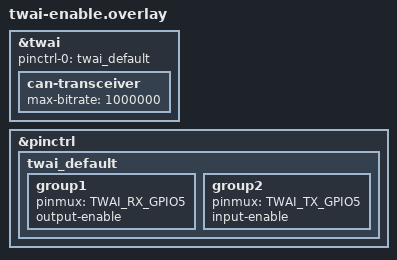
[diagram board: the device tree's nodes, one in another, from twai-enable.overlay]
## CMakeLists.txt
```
# SPDX-License-Identifier: Apache-2.0

cmake_minimum_required(VERSION 3.20.0)
find_package(Zephyr REQUIRED HINTS $ENV{ZEPHYR_BASE})
project(integration)

target_sources(app PRIVATE src/common.c)
target_sources(app PRIVATE src/classic.c)
target_sources(app PRIVATE src/transceiver.c)
target_sources(app PRIVATE src/utilities.c)
target_sources_ifdef(CONFIG_CAN_FD_MODE app PRIVATE src/canfd.c)
target_sources_ifdef(CONFIG_CAN_STATS app PRIVATE src/stats.c)
```

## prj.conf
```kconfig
CONFIG_CAN=y
CONFIG_CAN_FD_MODE=y
CONFIG_CAN_MANUAL_RECOVERY_MODE=y
CONFIG_STATS=y
CONFIG_CAN_STATS=y
CONFIG_TEST_USERSPACE=y
CONFIG_ZTEST=y
# The canfd test suite may be skipped
CONFIG_ZTEST_VERIFY_RUN_ALL=n
```

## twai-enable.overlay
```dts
/*
 * Copyright (c) 2022 Martin Jäger <martin@libre.solar>
 *
 * SPDX-License-Identifier: Apache-2.0
 */

/* Enable CAN bus */
&twai {
	status = "okay";
	pinctrl-0 = <&twai_default>;
	pinctrl-names = "default";

	can-transceiver {
		max-bitrate = <1000000>;
	};
};

&pinctrl {
	twai_default: twai_default {
		group1 {
			pinmux = <TWAI_RX_GPIO5>;
			output-enable;	/* enable internal loopback */
		};
		group2 {
			pinmux = <TWAI_TX_GPIO5>;
			input-enable;	/* enable internal loopback */
		};
};
};
```

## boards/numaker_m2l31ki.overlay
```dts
/* SPDX-License-Identifier: Apache-2.0 */

/ {
	chosen {
		zephyr,canbus = &canfd0;
	};
};

&pinctrl {
	/* CAN TX/RX --> UNO D3/D2 */
	canfd0_default: canfd0_default {
		group0 {
			pinmux = <PC5MFP_CANFD0_TXD>,
				 <PC4MFP_CANFD0_RXD>;
		};
	};
};

&canfd0 {
	pinctrl-0 = <&canfd0_default>;
	pinctrl-names = "default";
	status = "okay";
};
```

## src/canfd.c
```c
/*
 * Copyright (c) 2022 Vestas Wind Systems A/S
 * Copyright (c) 2019 Alexander Wachter
 *
 * SPDX-License-Identifier: Apache-2.0
 */

#include <zephyr/drivers/can.h>
#include <zephyr/ztest.h>

#include "common.h"

/**
 * @addtogroup t_can_driver
 * @{
 * @defgroup t_can_canfd test_can_canfd
 * @}
 */

static void tx_std_callback_1(const struct device *dev, int error, void *user_data)
{
	const struct can_frame *frame = user_data;

	k_sem_give(&tx_callback_sem);

	zassert_equal(dev, can_dev, "CAN device does not match");
	zassert_equal(frame->id, TEST_CAN_STD_ID_1, "ID does not match");
}

static void tx_std_callback_2(const struct device *dev, int error, void *user_data)
{
	const struct can_frame *frame = user_data;

	k_sem_give(&tx_callback_sem);

	zassert_equal(dev, can_dev, "CAN device does not match");
	zassert_equal(frame->id, TEST_CAN_STD_ID_2, "ID does not match");
}

static void rx_std_callback_1(const struct device *dev, struct can_frame *frame, void *user_data)
{
	struct can_filter *filter = user_data;

	assert_frame_equal(frame, &test_std_frame_1, 0);
	zassert_equal(dev, can_dev, "CAN device does not match");
	zassert_equal_ptr(filter, &test_std_filter_1, "filter does not match");

	k_sem_give(&rx_callback_sem);
}

static void rx_std_callback_2(const struct device *dev, struct can_frame *frame, void *user_data)
{
	struct can_filter *filter = user_data;

	assert_frame_equal(frame, &test_std_frame_2, 0);
	zassert_equal(dev, can_dev, "CAN device does not match");
	zassert_equal_ptr(filter, &test_std_filter_2, "filter does not match");

	k_sem_give(&rx_callback_sem);
}

static void rx_std_callback_fd_1(const struct device *dev, struct can_frame *frame,
				 void *user_data)
{
	struct can_filter *filter = user_data;

	assert_frame_equal(frame, &test_std_fdf_frame_1, 0);
	zassert_equal(dev, can_dev, "CAN device does not match");
	zassert_equal_ptr(filter, &test_std_filter_1, "filter does not match");

	k_sem_give(&rx_callback_sem);
}

static void rx_std_callback_fd_2(const struct device *dev, struct can_frame *frame,
				 void *user_data)
{
	struct can_filter *filter = user_data;

	assert_frame_equal(frame, &test_std_fdf_frame_2, 0);
	zassert_equal(dev, can_dev, "CAN device does not match");
	zassert_equal_ptr(filter, &test_std_filter_2, "filter does not match");

	k_sem_give(&rx_callback_sem);
}

/**
 * @brief Send a CAN test frame with asserts.
 *
 * This function will block until the frame is transmitted or a test timeout
 * occurs.
 *
 * @param dev   Pointer to the device structure for the driver instance.
 * @param frame Pointer to the CAN frame to send.
 */
static void send_test_frame(const struct device *dev, const struct can_frame *frame)
{
	int err;

	err = can_send(dev, frame, TEST_SEND_TIMEOUT, NULL, NULL);
	zassert_not_equal(err, -EBUSY, "arbitration lost in loopback mode");
	zassert_equal(err, 0, "failed to send frame (err %d)", err);
}

/**
 * @brief Send a CAN test frame with asserts.
 *
 * This function will block until the frame is queued or a test timeout
 * occurs.
 *
 * @param dev      Pointer to the device structure for the driver instance.
 * @param frame    Pointer to the CAN frame to send.
 * @param callback Transmit callback function.
 */
static void send_test_frame_nowait(const struct device *dev, const struct can_frame *frame,
				   can_tx_callback_t callback)
{
	int err;

	err = can_send(dev, frame, TEST_SEND_TIMEOUT, callback, (void *)frame);
	zassert_not_equal(err, -EBUSY, "arbitration lost in loopback mode");
	zassert_equal(err, 0, "failed to send frame (err %d)", err);
}

/**
 * @brief Add a CAN message queue with asserts.
 *
 * @param dev    Pointer to the device structure for the driver instance.
 * @param filter CAN filter for the CAN message queue.
 *
 * @return CAN filter ID.
 */
static inline int add_rx_msgq(const struct device *dev, const struct can_filter *filter)
{
	int filter_id;

	filter_id = can_add_rx_filter_msgq(dev, &can_msgq, filter);
	zassert_not_equal(filter_id, -ENOSPC, "no filters available");
	zassert_true(filter_id >= 0, "negative filter number");

	return filter_id;
}

/**
 * @brief Add a CAN filter with asserts.
 *
 * @param dev      Pointer to the device structure for the driver instance.
 * @param filter   CAN filter.
 * @param callback Receive callback function.
 *
 * @return CAN filter ID.
 */
static inline int add_rx_filter(const struct device *dev,
				const struct can_filter *filter,
				can_rx_callback_t callback)
{
	int filter_id;

	k_sem_reset(&rx_callback_sem);

	filter_id = can_add_rx_filter(dev, callback, (void *)filter, filter);
	zassert_not_equal(filter_id, -ENOSPC, "no filters available");
	zassert_true(filter_id >= 0, "negative filter number");

	return filter_id;
}

/**
 * @brief Perform a send/receive test with a set of CAN ID filters and CAN frames.
 *
 * @param filter1 CAN filter 1
 * @param filter2 CAN filter 2
 * @param frame1  CAN frame 1
 * @param frame2  CAN frame 2
 */
static void send_receive(const struct can_filter *filter1,
			 const struct can_filter *filter2,
			 const struct can_frame *frame1,
			 const struct can_frame *frame2)
{
	struct can_frame frame_buffer;
	int filter_id_1;
	int filter_id_2;
	int err;

	filter_id_1 = add_rx_msgq(can_dev, filter1);
	send_test_frame(can_dev, frame1);

	err = k_msgq_get(&can_msgq, &frame_buffer, TEST_RECEIVE_TIMEOUT);
	zassert_equal(err, 0, "receive timeout");

	assert_frame_equal(&frame_buffer, frame1, 0);
	can_remove_rx_filter(can_dev, filter_id_1);

	k_sem_reset(&tx_callback_sem);

	if ((frame1->flags & CAN_FRAME_FDF) != 0) {
		filter_id_1 = add_rx_filter(can_dev, filter1, rx_std_callback_fd_1);
	} else {
		filter_id_1 = add_rx_filter(can_dev, filter1, rx_std_callback_1);
	}

	if ((frame2->flags & CAN_FRAME_FDF) != 0) {
		filter_id_2 = add_rx_filter(can_dev, filter2, rx_std_callback_fd_2);
	} else {
		filter_id_2 = add_rx_filter(can_dev, filter2, rx_std_callback_2);
	}

	send_test_frame_nowait(can_dev, frame1, tx_std_callback_1);
	send_test_frame_nowait(can_dev, frame2, tx_std_callback_2);

	err = k_sem_take(&rx_callback_sem, TEST_RECEIVE_TIMEOUT);
	zassert_equal(err, 0, "receive timeout");

	err = k_sem_take(&rx_callback_sem, TEST_RECEIVE_TIMEOUT);
	zassert_equal(err, 0, "receive timeout");

	err = k_sem_take(&tx_callback_sem, TEST_SEND_TIMEOUT);
	zassert_equal(err, 0, "missing TX callback");

	err = k_sem_take(&tx_callback_sem, TEST_SEND_TIMEOUT);
	zassert_equal(err, 0, "missing TX callback");

	can_remove_rx_filter(can_dev, filter_id_1);
	can_remove_rx_filter(can_dev, filter_id_2);
}

/**
 * @brief Test getting the CAN controller capabilities.
 */
ZTEST(canfd, test_canfd_get_capabilities)
{
	can_mode_t cap;
	int err;

	err = can_get_capabilities(can_dev, &cap);
	zassert_equal(err, 0, "failed to get CAN capabilities (err %d)", err);
	zassert_not_equal(cap & (CAN_MODE_LOOPBACK | CAN_MODE_FD), 0,
			  "CAN FD loopback mode not supported");
}

/**
 * @brief Test send/receive with standard (11-bit) CAN IDs and classic CAN frames.
 */
ZTEST(canfd, test_send_receive_classic)
{
	send_receive(&test_std_filter_1, &test_std_filter_2,
		     &test_std_frame_1, &test_std_frame_2);
}

/**
 * @brief Test send/receive with standard (11-bit) CAN IDs and CAN FD frames.
 */
ZTEST(canfd, test_send_receive_fd)
{
	send_receive(&test_std_filter_1, &test_std_filter_2,
		     &test_std_fdf_frame_1, &test_std_fdf_frame_2);
}

/**
 * @brief Test send/receive with (11-bit) CAN IDs, mixed classic and CAN FD frames.
 */
ZTEST(canfd, test_send_receive_mixed)
{
	send_receive(&test_std_filter_1, &test_std_filter_2,
		     &test_std_fdf_frame_1, &test_std_frame_2);
}

/**
 * @brief Test that CAN RX filters are preserved through CAN controller mode changes.
 */
static void check_filters_preserved_between_modes(can_mode_t first, can_mode_t second)
{
	struct can_frame frame;
	enum can_state state;
	int filter_id_1;
	int filter_id_2;
	int err;

	/* Stop controller and set first mode */
	err = can_stop(can_dev);
	zassert_equal(err, 0, "failed to stop CAN controller (err %d)", err);

	err = can_get_state(can_dev, &state, NULL);
	zassert_equal(err, 0, "failed to get CAN state (err %d)", err);
	zassert_equal(state, CAN_STATE_STOPPED, "CAN controller not stopped");

	err = can_set_mode(can_dev, first | CAN_MODE_LOOPBACK);
	zassert_equal(err, 0, "failed to set first loopback mode (err %d)", err);
	zassert_equal(first | CAN_MODE_LOOPBACK, can_get_mode(can_dev));

	err = can_start(can_dev);
	zassert_equal(err, 0, "failed to start CAN controller (err %d)", err);

	/* Add classic CAN and CAN FD filter */
	filter_id_1 = add_rx_msgq(can_dev, &test_std_filter_1);
	filter_id_2 = add_rx_msgq(can_dev, &test_std_filter_2);

	/* Verify classic filter in first mode */
	send_test_frame(can_dev, &test_std_frame_1);
	err = k_msgq_get(&can_msgq, &frame, TEST_RECEIVE_TIMEOUT);
	zassert_equal(err, 0, "receive timeout");
	assert_frame_equal(&frame, &test_std_frame_1, 0);

	if ((first & CAN_MODE_FD) != 0) {
		/* Verify CAN FD filter in first mode */
		send_test_frame(can_dev, &test_std_fdf_frame_2);
		err = k_msgq_get(&can_msgq, &frame, TEST_RECEIVE_TIMEOUT);
		zassert_equal(err, 0, "receive timeout");
		assert_frame_equal(&frame, &test_std_fdf_frame_2, 0);
	}

	/* Stop controller and set second mode */
	err = can_stop(can_dev);
	zassert_equal(err, 0, "failed to stop CAN controller (err %d)", err);

	err = can_get_state(can_dev, &state, NULL);
	zassert_equal(err, 0, "failed to get CAN state (err %d)", err);
	zassert_equal(state, CAN_STATE_STOPPED, "CAN controller not stopped");

	err = can_set_mode(can_dev, second | CAN_MODE_LOOPBACK);
	zassert_equal(err, 0, "failed to set second loopback mode (err %d)", err);
	zassert_equal(second | CAN_MODE_LOOPBACK, can_get_mode(can_dev));

	err = can_start(can_dev);
	zassert_equal(err, 0, "failed to start CAN controller (err %d)", err);

	/* Verify classic filter in second mode */
	send_test_frame(can_dev, &test_std_frame_1);
	err = k_msgq_get(&can_msgq, &frame, TEST_RECEIVE_TIMEOUT);
	zassert_equal(err, 0, "receive timeout");
	assert_frame_equal(&frame, &test_std_frame_1, 0);

	if ((second & CAN_MODE_FD) != 0) {
		/* Verify CAN FD filter in second mode */
		send_test_frame(can_dev, &test_std_fdf_frame_2);
		err = k_msgq_get(&can_msgq, &frame, TEST_RECEIVE_TIMEOUT);
		zassert_equal(err, 0, "receive timeout");
		assert_frame_equal(&frame, &test_std_fdf_frame_2, 0);
	}

	/* Stop controller and restore CAN FD loopback mode */
	err = can_stop(can_dev);
	zassert_equal(err, 0, "failed to stop CAN controller (err %d)", err);

	err = can_get_state(can_dev, &state, NULL);
	zassert_equal(err, 0, "failed to get CAN state (err %d)", err);
	zassert_equal(state, CAN_STATE_STOPPED, "CAN controller not stopped");

	err = can_set_mode(can_dev, CAN_MODE_FD | CAN_MODE_LOOPBACK);
	zassert_equal(err, 0, "failed to set loopback-mode (err %d)", err);
	zassert_equal(CAN_MODE_FD | CAN_MODE_LOOPBACK, can_get_mode(can_dev));

	err = can_start(can_dev);
	zassert_equal(err, 0, "failed to start CAN controller (err %d)", err);

	can_remove_rx_filter(can_dev, filter_id_1);
	can_remove_rx_filter(can_dev, filter_id_2);
}

/**
 * @brief Test that CAN RX filters are preserved through CAN controller mode changes between classic
 * CAN and CAN FD.
 */
ZTEST_USER(canfd, test_filters_preserved_through_classic_to_fd_mode_change)
{
	check_filters_preserved_between_modes(CAN_MODE_NORMAL, CAN_MODE_FD);
}

/**
 * @brief Test that CAN RX filters are preserved through CAN controller mode changes between CAN FD
 * and classic CAN.
 */
ZTEST_USER(canfd, test_filters_preserved_through_fd_to_classic_mode_change)
{
	check_filters_preserved_between_modes(CAN_MODE_FD, CAN_MODE_NORMAL);
}

/**
 * @brief Test that the minimum timing values for the data phase can be set.
 */
ZTEST_USER(canfd, test_set_timing_data_min)
{
	int err;

	err = can_stop(can_dev);
	zassert_equal(err, 0, "failed to stop CAN controller (err %d)", err);

	err = can_set_timing_data(can_dev, can_get_timing_data_min(can_dev));
	zassert_equal(err, 0, "failed to set minimum timing data parameters (err %d)", err);

	err = can_set_bitrate_data(can_dev, CONFIG_CAN_DEFAULT_BITRATE_DATA);
	zassert_equal(err, 0, "failed to restore default data bitrate");

	err = can_start(can_dev);
	zassert_equal(err, 0, "failed to start CAN controller (err %d)", err);
}

/**
 * @brief Test setting a too high data phase bitrate.
 */
ZTEST_USER(canfd, test_set_bitrate_too_high)
{
	uint32_t max = can_get_bitrate_max(can_dev);
	int err;

	err = can_stop(can_dev);
	zassert_equal(err, 0, "failed to stop CAN controller (err %d)", err);

	err = can_set_bitrate_data(can_dev, max + 1);
	zassert_equal(err, -ENOTSUP, "too high data phase bitrate accepted");

	err = can_start(can_dev);
	zassert_equal(err, 0, "failed to start CAN controller (err %d)", err);
}

/**
 * @brief Test using an invalid sample point.
 */
ZTEST_USER(canfd, test_invalid_sample_point)
{
	struct can_timing timing;
	int err;

	err = can_calc_timing_data(can_dev, &timing, TEST_BITRATE_3, 1000);
	zassert_equal(err, -EINVAL, "invalid sample point of 100.0% accepted (err %d)", err);
}

/**
 * @brief Test that the maximum timing values for the data phase can be set.
 */
ZTEST_USER(canfd, test_set_timing_data_max)
{
	int err;

	err = can_stop(can_dev);
	zassert_equal(err, 0, "failed to stop CAN controller (err %d)", err);

	err = can_set_timing_data(can_dev, can_get_timing_data_max(can_dev));
	zassert_equal(err, 0, "failed to set maximum timing data parameters (err %d)", err);

	err = can_set_bitrate_data(can_dev, CONFIG_CAN_DEFAULT_BITRATE_DATA);
	zassert_equal(err, 0, "failed to restore default data bitrate");

	err = can_start(can_dev);
	zassert_equal(err, 0, "failed to start CAN controller (err %d)", err);
}

/**
 * @brief Test setting data phase bitrate is not allowed while started.
 */
ZTEST_USER(canfd, test_set_bitrate_data_while_started)
{
	int err;

	err = can_set_bitrate_data(can_dev, TEST_BITRATE_3);
	zassert_not_equal(err, 0, "changed data bitrate while started");
	zassert_equal(err, -EBUSY, "wrong error return code (err %d)", err);
}

/**
 * @brief Test setting data phase timing is not allowed while started.
 */
ZTEST_USER(canfd, test_set_timing_data_while_started)
{
	struct can_timing timing = { 0 };
	int err;

	err = can_calc_timing_data(can_dev, &timing, TEST_BITRATE_3, TEST_SAMPLE_POINT);
	zassert_ok(err, "failed to calculate data timing (err %d)", err);

	err = can_set_timing_data(can_dev, &timing);
	zassert_not_equal(err, 0, "changed data timing while started");
	zassert_equal(err, -EBUSY, "wrong error return code (err %d)", err);
}

static bool canfd_predicate(const void *state)
{
	can_mode_t cap;
	int err;

	ARG_UNUSED(state);

	if (!device_is_ready(can_dev)) {
		TC_PRINT("CAN device not ready");
		return false;
	}

	err = can_get_capabilities(can_dev, &cap);
	zassert_equal(err, 0, "failed to get CAN controller capabilities (err %d)", err);

	if ((cap & CAN_MODE_FD) == 0) {
		return false;
	}

	return true;
}

void *canfd_setup(void)
{
	can_common_test_setup(CAN_MODE_LOOPBACK | CAN_MODE_FD);

	return NULL;
}

ZTEST_SUITE(canfd, canfd_predicate, canfd_setup, NULL, NULL, NULL);
```

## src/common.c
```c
/*
 * Copyright (c) 2022 Vestas Wind Systems A/S
 * Copyright (c) 2019 Alexander Wachter
 *
 * SPDX-License-Identifier: Apache-2.0
 */

#include <zephyr/drivers/can.h>
#include <zephyr/kernel.h>
#include <zephyr/ztest.h>

#include "common.h"

/**
 * @brief Global variables.
 */
ZTEST_DMEM const struct device *const can_dev = DEVICE_DT_GET(DT_CHOSEN(zephyr_canbus));
ZTEST_DMEM const struct device *const can_phy =
	DEVICE_DT_GET_OR_NULL(DT_PHANDLE(DT_CHOSEN(zephyr_canbus), phys));
struct k_sem rx_callback_sem;
struct k_sem tx_callback_sem;

CAN_MSGQ_DEFINE(can_msgq, 5);

/**
 * @brief Standard (11-bit) CAN ID frame 1.
 */
const struct can_frame test_std_frame_1 = {
	.flags   = 0,
	.id      = TEST_CAN_STD_ID_1,
	.dlc     = 8,
	.data    = {1, 2, 3, 4, 5, 6, 7, 8}
};

/**
 * @brief Standard (11-bit) CAN ID frame 2.
 */
const struct can_frame test_std_frame_2 = {
	.flags   = 0,
	.id      = TEST_CAN_STD_ID_2,
	.dlc     = 8,
	.data    = {1, 2, 3, 4, 5, 6, 7, 8}
};

/**
 * @brief Extended (29-bit) CAN ID frame 1.
 */
const struct can_frame test_ext_frame_1 = {
	.flags   = CAN_FRAME_IDE,
	.id      = TEST_CAN_EXT_ID_1,
	.dlc     = 8,
	.data    = {1, 2, 3, 4, 5, 6, 7, 8}
};

/**
 * @brief Extended (29-bit) CAN ID frame 1.
 */
const struct can_frame test_ext_frame_2 = {
	.flags   = CAN_FRAME_IDE,
	.id      = TEST_CAN_EXT_ID_2,
	.dlc     = 8,
	.data    = {1, 2, 3, 4, 5, 6, 7, 8}
};

/**
 * @brief Standard (11-bit) CAN ID RTR frame 1.
 */
const struct can_frame test_std_rtr_frame_1 = {
	.flags   = CAN_FRAME_RTR,
	.id      = TEST_CAN_STD_ID_1,
	.dlc     = 0,
	.data    = {0}
};

/**
 * @brief Extended (29-bit) CAN ID RTR frame 1.
 */
const struct can_frame test_ext_rtr_frame_1 = {
	.flags   = CAN_FRAME_IDE | CAN_FRAME_RTR,
	.id      = TEST_CAN_EXT_ID_1,
	.dlc     = 0,
	.data    = {0}
};

#ifdef CONFIG_CAN_FD_MODE
/**
 * @brief Standard (11-bit) CAN ID frame 1 with CAN FD payload.
 */
const struct can_frame test_std_fdf_frame_1 = {
	.flags   = CAN_FRAME_FDF | CAN_FRAME_BRS,
	.id      = TEST_CAN_STD_ID_1,
	.dlc     = 0xf,
	.data    = { 1,  2,  3,  4,  5,  6,  7,  8,  9, 10, 11, 12, 13, 14, 15,
		    16, 17, 18, 19, 20, 21, 22, 23, 24, 25, 26, 27, 28, 29, 30,
		    31, 32, 33, 34, 35, 36, 37, 38, 39, 40, 41, 42, 43, 44, 45,
		    46, 47, 48, 49, 50, 51, 52, 53, 54, 55, 56, 57, 58, 59, 60,
		    61, 62, 63, 64 }
};

/**
 * @brief Standard (11-bit) CAN ID frame 1 with CAN FD payload.
 */
const struct can_frame test_std_fdf_frame_2 = {
	.flags   = CAN_FRAME_FDF | CAN_FRAME_BRS,
	.id      = TEST_CAN_STD_ID_2,
	.dlc     = 0xf,
	.data    = { 1,  2,  3,  4,  5,  6,  7,  8,  9, 10, 11, 12, 13, 14, 15,
		    16, 17, 18, 19, 20, 21, 22, 23, 24, 25, 26, 27, 28, 29, 30,
		    31, 32, 33, 34, 35, 36, 37, 38, 39, 40, 41, 42, 43, 44, 45,
		    46, 47, 48, 49, 50, 51, 52, 53, 54, 55, 56, 57, 58, 59, 60,
		    61, 62, 63, 64 }
};
#endif /* CONFIG_CAN_FD_MODE */

/**
 * @brief Standard (11-bit) CAN ID filter 1. This filter matches
 * ``test_std_frame_1``.
 */
const struct can_filter test_std_filter_1 = {
	.flags = 0U,
	.id = TEST_CAN_STD_ID_1,
	.mask = CAN_STD_ID_MASK
};

/**
 * @brief Standard (11-bit) CAN ID filter 2. This filter matches
 * ``test_std_frame_2``.
 */
const struct can_filter test_std_filter_2 = {
	.flags = 0U,
	.id = TEST_CAN_STD_ID_2,
	.mask = CAN_STD_ID_MASK
};

/**
 * @brief Standard (11-bit) CAN ID masked filter 1. This filter matches
 * ``test_std_frame_1``.
 */
const struct can_filter test_std_masked_filter_1 = {
	.flags = 0U,
	.id = TEST_CAN_STD_MASK_ID_1,
	.mask = TEST_CAN_STD_MASK
};

/**
 * @brief Standard (11-bit) CAN ID masked filter 2. This filter matches
 * ``test_std_frame_2``.
 */
const struct can_filter test_std_masked_filter_2 = {
	.flags = 0U,
	.id = TEST_CAN_STD_MASK_ID_2,
	.mask = TEST_CAN_STD_MASK
};

/**
 * @brief Extended (29-bit) CAN ID filter 1. This filter matches
 * ``test_ext_frame_1``.
 */
const struct can_filter test_ext_filter_1 = {
	.flags = CAN_FILTER_IDE,
	.id = TEST_CAN_EXT_ID_1,
	.mask = CAN_EXT_ID_MASK
};

/**
 * @brief Extended (29-bit) CAN ID filter 2. This filter matches
 * ``test_ext_frame_2``.
 */
const struct can_filter test_ext_filter_2 = {
	.flags = CAN_FILTER_IDE,
	.id = TEST_CAN_EXT_ID_2,
	.mask = CAN_EXT_ID_MASK
};

/**
 * @brief Extended (29-bit) CAN ID masked filter 1. This filter matches
 * ``test_ext_frame_1``.
 */
const struct can_filter test_ext_masked_filter_1 = {
	.flags = CAN_FILTER_IDE,
	.id = TEST_CAN_EXT_MASK_ID_1,
	.mask = TEST_CAN_EXT_MASK
};

/**
 * @brief Extended (29-bit) CAN ID masked filter 2. This filter matches
 * ``test_ext_frame_2``.
 */
const struct can_filter test_ext_masked_filter_2 = {
	.flags = CAN_FILTER_IDE,
	.id = TEST_CAN_EXT_MASK_ID_2,
	.mask = TEST_CAN_EXT_MASK
};

/**
 * @brief Standard (11-bit) CAN ID filter. This filter matches
 * ``TEST_CAN_SOME_STD_ID``.
 */
const struct can_filter test_std_some_filter = {
	.flags = 0U,
	.id = TEST_CAN_SOME_STD_ID,
	.mask = CAN_STD_ID_MASK
};

/**
 * @brief Assert that two CAN frames are equal given a CAN ID mask.
 *
 * @param frame1  First CAN frame.
 * @param frame2  Second CAN frame.
 * @param id_mask CAN ID mask.
 */
void assert_frame_equal(const struct can_frame *frame1,
			const struct can_frame *frame2,
			uint32_t id_mask)
{
	zassert_equal(frame1->flags, frame2->flags, "Flags do not match");
	zassert_equal(frame1->id | id_mask, frame2->id | id_mask, "ID does not match");
	zassert_equal(frame1->dlc, frame2->dlc, "DLC does not match");

	if ((frame1->flags & CAN_FRAME_RTR) == 0U) {
		zassert_mem_equal(frame1->data, frame2->data, can_dlc_to_bytes(frame1->dlc),
				  "Received data differ");
	}
}

void can_common_test_setup(can_mode_t initial_mode)
{
	int err;

	k_sem_init(&rx_callback_sem, 0, 2);
	k_sem_init(&tx_callback_sem, 0, 2);

	k_object_access_grant(&can_msgq, k_current_get());
	k_object_access_grant(can_dev, k_current_get());

	zassert_true(device_is_ready(can_dev), "CAN device not ready");

	(void)can_stop(can_dev);

	err = can_set_mode(can_dev, initial_mode);
	zassert_equal(err, 0, "failed to set initial mode (err %d)", err);
	zassert_equal(initial_mode, can_get_mode(can_dev));

	err = can_start(can_dev);
	zassert_equal(err, 0, "failed to start CAN controller (err %d)", err);
}
```

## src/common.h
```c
/*
 * Copyright (c) 2022 Vestas Wind Systems A/S
 * Copyright (c) 2019 Alexander Wachter
 *
 * SPDX-License-Identifier: Apache-2.0
 */

#include <zephyr/device.h>
#include <zephyr/drivers/can.h>
#include <zephyr/kernel.h>

/**
 * Test bitrates in bits/second.
 */
#define TEST_BITRATE_1 125000
#define TEST_BITRATE_2 250000
#define TEST_BITRATE_3 1000000

/**
 * Test sample points in per mille.
 */
#define TEST_SAMPLE_POINT 875
#define TEST_SAMPLE_POINT_2 750

/**
 * @brief Test timeouts.
 */
#define TEST_SEND_TIMEOUT    K_MSEC(100)
#define TEST_RECEIVE_TIMEOUT K_MSEC(100)
#define TEST_RECOVER_TIMEOUT K_MSEC(100)

/**
 * @brief Standard (11-bit) CAN IDs and masks used for testing.
 */
#define TEST_CAN_STD_ID_1      0x555
#define TEST_CAN_STD_ID_2      0x565
#define TEST_CAN_STD_MASK_ID_1 0x55A
#define TEST_CAN_STD_MASK_ID_2 0x56A
#define TEST_CAN_STD_MASK      0x7F0
#define TEST_CAN_SOME_STD_ID   0x123

/**
 * @brief Extended (29-bit) CAN IDs and masks used for testing.
 */
#define TEST_CAN_EXT_ID_1      0x15555555
#define TEST_CAN_EXT_ID_2      0x15555565
#define TEST_CAN_EXT_MASK_ID_1 0x1555555A
#define TEST_CAN_EXT_MASK_ID_2 0x1555556A
#define TEST_CAN_EXT_MASK      0x1FFFFFF0

/**
 * @brief Common variables.
 */
extern ZTEST_DMEM const struct device *const can_dev;
extern ZTEST_DMEM const struct device *const can_phy;
extern struct k_sem rx_callback_sem;
extern struct k_sem tx_callback_sem;
extern struct k_msgq can_msgq;

/**
 * @brief Standard (11-bit) CAN ID frame 1.
 */
extern const struct can_frame test_std_frame_1;

/**
 * @brief Standard (11-bit) CAN ID frame 2.
 */
extern const struct can_frame test_std_frame_2;

/**
 * @brief Extended (29-bit) CAN ID frame 1.
 */
extern const struct can_frame test_ext_frame_1;

/**
 * @brief Extended (29-bit) CAN ID frame 1.
 */
extern const struct can_frame test_ext_frame_2;

/**
 * @brief Standard (11-bit) CAN ID RTR frame 1.
 */
extern const struct can_frame test_std_rtr_frame_1;

/**
 * @brief Extended (29-bit) CAN ID RTR frame 1.
 */
extern const struct can_frame test_ext_rtr_frame_1;

#ifdef CONFIG_CAN_FD_MODE
/**
 * @brief Standard (11-bit) CAN ID frame 1 with CAN FD payload.
 */
extern const struct can_frame test_std_fdf_frame_1;

/**
 * @brief Standard (11-bit) CAN ID frame 2 with CAN FD payload.
 */
extern const struct can_frame test_std_fdf_frame_2;
#endif /* CONFIG_CAN_FD_MODE */

/**
 * @brief Standard (11-bit) CAN ID filter 1. This filter matches
 * ``test_std_frame_1`` and ``test_std_fdf_frame_1``.
 */
extern const struct can_filter test_std_filter_1;

/**
 * @brief Standard (11-bit) CAN ID filter 2. This filter matches
 * ``test_std_frame_2`` and ``test_std_fdf_frame_2``.
 */
extern const struct can_filter test_std_filter_2;

/**
 * @brief Standard (11-bit) CAN ID masked filter 1. This filter matches
 * ``test_std_frame_1``.
 */
extern const struct can_filter test_std_masked_filter_1;

/**
 * @brief Standard (11-bit) CAN ID masked filter 2. This filter matches
 * ``test_std_frame_2``.
 */
extern const struct can_filter test_std_masked_filter_2;

/**
 * @brief Extended (29-bit) CAN ID filter 1. This filter matches
 * ``test_ext_frame_1``.
 */
extern const struct can_filter test_ext_filter_1;

/**
 * @brief Extended (29-bit) CAN ID filter 2. This filter matches
 * ``test_ext_frame_2``.
 */
extern const struct can_filter test_ext_filter_2;

/**
 * @brief Extended (29-bit) CAN ID masked filter 1. This filter matches
 * ``test_ext_frame_1``.
 */
extern const struct can_filter test_ext_masked_filter_1;

/**
 * @brief Extended (29-bit) CAN ID masked filter 2. This filter matches
 * ``test_ext_frame_2``.
 */
extern const struct can_filter test_ext_masked_filter_2;

/**
 * @brief Standard (11-bit) CAN ID filter. This filter matches
 * ``TEST_CAN_SOME_STD_ID``.
 */
extern const struct can_filter test_std_some_filter;

/**
 * @brief Assert that two CAN frames are equal given a CAN ID mask.
 *
 * @param frame1  First CAN frame.
 * @param frame2  Second CAN frame.
 * @param id_mask CAN ID mask.
 */
void assert_frame_equal(const struct can_frame *frame1,
			const struct can_frame *frame2,
			uint32_t id_mask);

/**
 * @brief Common setup function for the CAN controller device under test.
 *
 * @param initial_mode Initial CAN controller operational mode.
 */
void can_common_test_setup(can_mode_t initial_mode);
```

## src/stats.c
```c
/*
 * Copyright (c) 2023 Vestas Wind Systems A/S
 *
 * SPDX-License-Identifier: Apache-2.0
 */

#include <zephyr/drivers/can.h>
#include <zephyr/ztest.h>

#include "common.h"

/**
 * @addtogroup t_driver_can
 * @{
 * @defgroup t_can_stats test_can_stats
 * @}
 */

/**
 * @brief Test that CAN statistics can be accessed from user mode threads.
 */
ZTEST_USER(can_stats, test_can_stats_accessors)
{
	uint32_t val;

	val = can_stats_get_bit_errors(can_dev);
	val = can_stats_get_bit0_errors(can_dev);
	val = can_stats_get_bit1_errors(can_dev);
	val = can_stats_get_stuff_errors(can_dev);
	val = can_stats_get_crc_errors(can_dev);
	val = can_stats_get_form_errors(can_dev);
	val = can_stats_get_ack_errors(can_dev);
	val = can_stats_get_rx_overruns(can_dev);
}

void *can_stats_setup(void)
{
	k_object_access_grant(can_dev, k_current_get());

	zassert_true(device_is_ready(can_dev), "CAN device not ready");

	return NULL;
}

ZTEST_SUITE(can_stats, NULL, can_stats_setup, NULL, NULL, NULL);
```

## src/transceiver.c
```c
/*
 * Copyright (c) 2024 Vestas Wind Systems A/S
 *
 * SPDX-License-Identifier: Apache-2.0
 */

#include <zephyr/drivers/can.h>
#include <zephyr/ztest.h>

#include "common.h"

/**
 * @addtogroup t_can_driver
 * @{
 * @defgroup t_can_transceiver test_can_transceiver
 * @}
 */

/**
 * @brief Test getting CAN transceiver device pointer.
 */
ZTEST_USER(can_transceiver, test_get_transceiver)
{
	const struct device *phy = can_get_transceiver(can_dev);

	zassert_equal(phy, can_phy, "wrong CAN transceiver device pointer returned");
}

static bool can_transceiver_predicate(const void *state)
{
	ARG_UNUSED(state);

	if (!device_is_ready(can_dev)) {
		TC_PRINT("CAN device not ready");
		return false;
	}

	if (!device_is_ready(can_phy)) {
		TC_PRINT("CAN transceiver device not ready");
		return false;
	}

	return true;
}

void *can_transceiver_setup(void)
{
	k_object_access_grant(can_dev, k_current_get());
	k_object_access_grant(can_phy, k_current_get());

	zassert_true(device_is_ready(can_dev), "CAN device not ready");
	zassert_true(device_is_ready(can_phy), "CAN transceiver device not ready");

	return NULL;
}

ZTEST_SUITE(can_transceiver, can_transceiver_predicate, can_transceiver_setup, NULL, NULL, NULL);
```

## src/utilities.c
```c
/*
 * Copyright (c) 2022 Vestas Wind Systems A/S
 * Copyright (c) 2019 Intel Corporation
 *
 * SPDX-License-Identifier: Apache-2.0
 */

#include <zephyr/drivers/can.h>
#include <zephyr/ztest.h>

#include "common.h"

/**
 * @addtogroup t_driver_can
 * @{
 * @defgroup t_can_utilities test_can_utilities
 * @}
 */

/**
 * @brief Test of @a can_dlc_to_bytes()
 */
ZTEST(can_utilities, test_can_dlc_to_bytes)
{
	uint8_t dlc;

	/* CAN 2.0B/CAN FD DLC, 0 to 8 data bytes */
	for (dlc = 0; dlc <= 8; dlc++) {
		zassert_equal(can_dlc_to_bytes(dlc), dlc, "wrong number of bytes for DLC %u", dlc);
	}

	/* CAN FD DLC, 12 to 64 data bytes in steps */
	zassert_equal(can_dlc_to_bytes(9),  12, "wrong number of bytes for DLC 9");
	zassert_equal(can_dlc_to_bytes(10), 16, "wrong number of bytes for DLC 10");
	zassert_equal(can_dlc_to_bytes(11), 20, "wrong number of bytes for DLC 11");
	zassert_equal(can_dlc_to_bytes(12), 24, "wrong number of bytes for DLC 12");
	zassert_equal(can_dlc_to_bytes(13), 32, "wrong number of bytes for DLC 13");
	zassert_equal(can_dlc_to_bytes(14), 48, "wrong number of bytes for DLC 14");
	zassert_equal(can_dlc_to_bytes(15), 64, "wrong number of bytes for DLC 15");
}

/**
 * @brief Test of @a can_bytes_to_dlc()
 */
ZTEST(can_utilities, test_can_bytes_to_dlc)
{
	uint8_t bytes;

	/* CAN 2.0B DLC, 0 to 8 data bytes */
	for (bytes = 0; bytes <= 8; bytes++) {
		zassert_equal(can_bytes_to_dlc(bytes), bytes, "wrong DLC for %u byte(s)", bytes);
	}

	/* CAN FD DLC, 12 to 64 data bytes in steps */
	zassert_equal(can_bytes_to_dlc(12), 9,  "wrong DLC for 12 bytes");
	zassert_equal(can_bytes_to_dlc(16), 10, "wrong DLC for 16 bytes");
	zassert_equal(can_bytes_to_dlc(20), 11, "wrong DLC for 20 bytes");
	zassert_equal(can_bytes_to_dlc(24), 12, "wrong DLC for 24 bytes");
	zassert_equal(can_bytes_to_dlc(32), 13, "wrong DLC for 32 bytes");
	zassert_equal(can_bytes_to_dlc(48), 14, "wrong DLC for 48 bytes");
	zassert_equal(can_bytes_to_dlc(64), 15, "wrong DLC for 64 bytes");
}

/**
 * @brief Test of @a can_frame_matches_filter()
 */
ZTEST(can_utilities, test_can_frame_matches_filter)
{
	const struct can_filter test_ext_filter_std_id_1 = {
		.flags = CAN_FILTER_IDE,
		.id = TEST_CAN_STD_ID_1,
		.mask = CAN_EXT_ID_MASK
	};

	/* Standard (11-bit) frames and filters */
	zassert_true(can_frame_matches_filter(&test_std_frame_1, &test_std_filter_1));
	zassert_true(can_frame_matches_filter(&test_std_frame_2, &test_std_filter_2));
	zassert_true(can_frame_matches_filter(&test_std_frame_1, &test_std_masked_filter_1));
	zassert_true(can_frame_matches_filter(&test_std_frame_2, &test_std_masked_filter_2));
	zassert_false(can_frame_matches_filter(&test_std_frame_1, &test_std_filter_2));
	zassert_false(can_frame_matches_filter(&test_std_frame_2, &test_std_filter_1));
	zassert_false(can_frame_matches_filter(&test_std_frame_1, &test_std_masked_filter_2));
	zassert_false(can_frame_matches_filter(&test_std_frame_2, &test_std_masked_filter_1));

	/* Extended (29-bit) frames and filters */
	zassert_true(can_frame_matches_filter(&test_ext_frame_1, &test_ext_filter_1));
	zassert_true(can_frame_matches_filter(&test_ext_frame_2, &test_ext_filter_2));
	zassert_true(can_frame_matches_filter(&test_ext_frame_1, &test_ext_masked_filter_1));
	zassert_true(can_frame_matches_filter(&test_ext_frame_2, &test_ext_masked_filter_2));
	zassert_false(can_frame_matches_filter(&test_ext_frame_1, &test_ext_filter_2));
	zassert_false(can_frame_matches_filter(&test_ext_frame_2, &test_ext_filter_1));
	zassert_false(can_frame_matches_filter(&test_ext_frame_1, &test_ext_masked_filter_2));
	zassert_false(can_frame_matches_filter(&test_ext_frame_2, &test_ext_masked_filter_1));

	/* Standard (11-bit) frames and extended (29-bit) filters */
	zassert_false(can_frame_matches_filter(&test_std_frame_1, &test_ext_filter_1));
	zassert_false(can_frame_matches_filter(&test_std_frame_2, &test_ext_filter_2));
	zassert_false(can_frame_matches_filter(&test_std_frame_1, &test_ext_masked_filter_1));
	zassert_false(can_frame_matches_filter(&test_std_frame_2, &test_ext_masked_filter_2));
	zassert_false(can_frame_matches_filter(&test_std_frame_1, &test_ext_filter_std_id_1));

	/* Extended (29-bit) frames and standard (11-bit) filters */
	zassert_false(can_frame_matches_filter(&test_ext_frame_1, &test_std_filter_1));
	zassert_false(can_frame_matches_filter(&test_ext_frame_2, &test_std_filter_2));
	zassert_false(can_frame_matches_filter(&test_ext_frame_1, &test_std_masked_filter_1));
	zassert_false(can_frame_matches_filter(&test_ext_frame_2, &test_std_masked_filter_2));

	/* Remote transmission request (RTR) frames */
	zassert_true(can_frame_matches_filter(&test_std_rtr_frame_1, &test_std_filter_1));
	zassert_true(can_frame_matches_filter(&test_ext_rtr_frame_1, &test_ext_filter_1));

#ifdef CONFIG_CAN_FD_MODE
	/* CAN FD format frames and filters */
	zassert_true(can_frame_matches_filter(&test_std_fdf_frame_1, &test_std_filter_1));
	zassert_true(can_frame_matches_filter(&test_std_fdf_frame_2, &test_std_filter_2));
#endif /* CONFIG_CAN_FD_MODE */
}

ZTEST_SUITE(can_utilities, NULL, NULL, NULL, NULL, NULL);
```
